# APM32F103x4 register map
File version: 1.0
CPU: CM3 r2p1, little endian, no MPU, no FPU, 4 interrupt priority bits
Registers are 32-bit, read-write, reset 0x0 unless marked. A register's access mark holds for its fields unless they carry their own. Offsets are from the block's base; [hi:lo] are bit positions; {n}, {i} and the like mark numbered series.

## PMU — Power control
Base 0x40007000
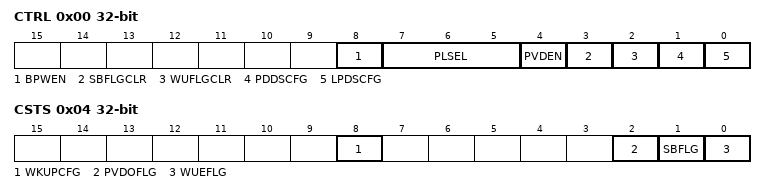
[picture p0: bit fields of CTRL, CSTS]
0x00 CTRL — Power control register (PMU_CTRL)
  [8] BPWEN — Disable Bakr Domain write protection
  [7:5] PLSEL — PVD Level Selection
  [4] PVDEN — Power Voltage Detector Enable
  [3] SBFLGCLR — Clear STANDBY Flag
  [2] WUFLGCLR — Clear Wake-up Flag
  [1] PDDSCFG — Power Down Deep Sleep
  [0] LPDSCFG — Low Power Deep Sleep
0x04 CSTS access per field — Power control/status register (PMU_CSTS)
  [8] WKUPCFG rw — Enable WKUP pin
  [2] PVDOFLG ro — PVD Output
  [1] SBFLG ro — STANDBY Flag
  [0] WUEFLG ro — Wake-Up Flag

## BAKPR — Bakr registers
Base 0x40006C00
{0x0+4i} DATA{i} (i=1..10) — Bakr data register (BAKPR_DATA)
  [15:0] DATA — Bakr data
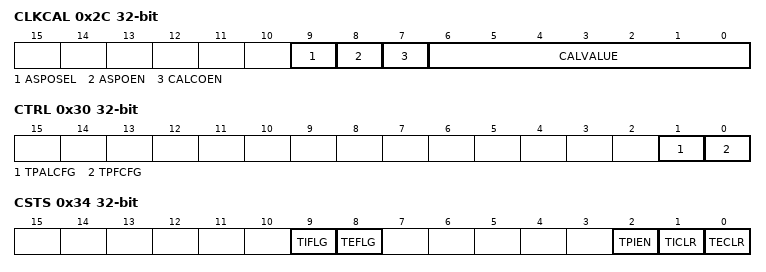
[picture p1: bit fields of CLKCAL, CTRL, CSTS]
0x2C CLKCAL — RTC clock calibration register (BAKPR_CLKCAL)
  [9] ASPOSEL — Alarm or second output selection
  [8] ASPOEN — Alarm or second output enable
  [7] CALCOEN — Calibration Clock Output
  [6:0] CALVALUE — Calibration value
0x30 CTRL — Bakr control register (BAKPR_CTRL)
  [1] TPALCFG — Tamper pin active level
  [0] TPFCFG — Tamper pin enable
0x34 CSTS access per field — Bakr control/status register (BAKPR_CSTS)
  [9] TIFLG ro — Tamper Interrupt Flag
  [8] TEFLG ro — Tamper Event Flag
  [2] TPIEN rw — Tamper Pin interrupt enable
  [1] TICLR wo — Clear Tamper Interrupt
  [0] TECLR wo — Clear Tamper event
{0x14+4i} DATA{i} (i=11..42) — Bakr data register (BAKPR_DATA)
  [15:0] DATA — Bakr data

## I2C1 — Inter integrated circuit 1
Base 0x40005400
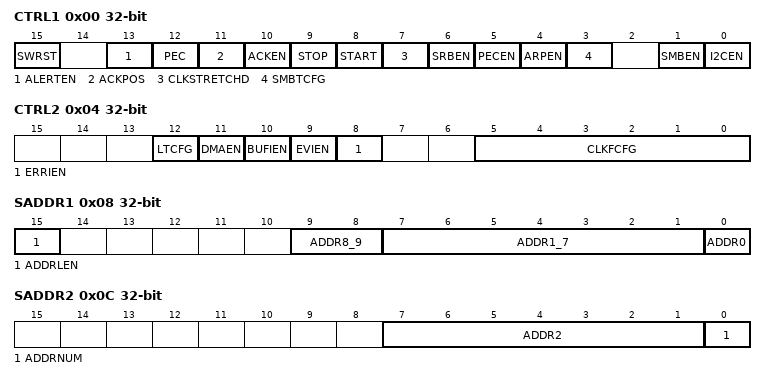
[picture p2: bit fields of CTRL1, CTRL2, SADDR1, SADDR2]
0x00 CTRL1 — Control register 1
  [15] SWRST — Software reset
  [13] ALERTEN — SMBus alert
  [12] PEC — Packet error checking
  [11] ACKPOS — Acknowledge/PEC Position (for data reception)
  [10] ACKEN — Acknowledge enable
  [9] STOP — Stop generation
  [8] START — Start generation
  [7] CLKSTRETCHD — Clock stretching disable (Slave mode)
  [6] SRBEN — General call enable
  [5] PECEN — PEC enable
  [4] ARPEN — ARP enable
  [3] SMBTCFG — SMBus type
  [1] SMBEN — SMBus mode
  [0] I2CEN — Peripheral enable
0x04 CTRL2 — Control register 2
  [12] LTCFG — DMA last transfer
  [11] DMAEN — DMA requests enable
  [10] BUFIEN — Buffer interrupt enable
  [9] EVIEN — Event interrupt enable
  [8] ERRIEN — Error interrupt enable
  [5:0] CLKFCFG — Peripheral clock frequency
0x08 SADDR1 — Own address register 1
  [15] ADDRLEN — Address Length Configure
  [9:8] ADDR8_9 — Interface address
  [7:1] ADDR1_7 — Interface address
  [0] ADDR0 — Interface address
0x0C SADDR2 — Own address register 2
  [7:1] ADDR2 — Interface address
  [0] ADDRNUM — Dual addressing mode enable
0x10 DATA
  [7:0] DATA — 8-bit data register
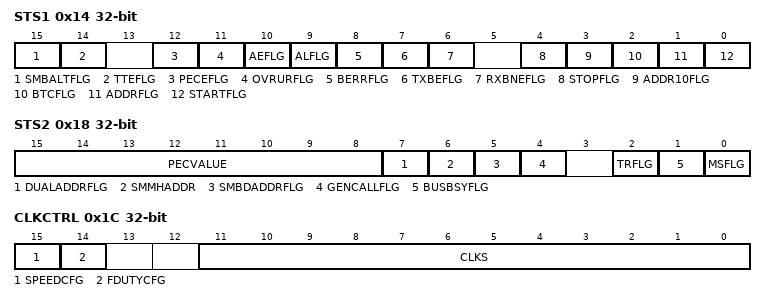
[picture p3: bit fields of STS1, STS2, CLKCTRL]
0x14 STS1 access per field — Status register 1
  [15] SMBALTFLG rw — SMBus alert
  [14] TTEFLG rw — Timeout or Tlow error
  [12] PECEFLG rw — PEC Error in reception
  [11] OVRURFLG rw — Overrun/Underrun
  [10] AEFLG rw — Acknowledge failure
  [9] ALFLG rw — Arbitration lost (master mode)
  [8] BERRFLG rw — Bus error
  [7] TXBEFLG ro — Data register empty (transmitters)
  [6] RXBNEFLG ro — Data register not empty (receivers)
  [4] STOPFLG ro — Stop detection (slave mode)
  [3] ADDR10FLG ro — 10-bit header sent (Master mode)
  [2] BTCFLG ro — Byte transfer finished
  [1] ADDRFLG ro — Address sent (master mode)/matched (slave mode)
  [0] STARTFLG ro — Start bit (Master mode)
0x18 STS2 ro — Status register 2
  [15:8] PECVALUE — acket error checking register
  [7] DUALADDRFLG — Dual flag (Slave mode)
  [6] SMMHADDR — SMBus host header (Slave mode)
  [5] SMBDADDRFLG — SMBus device default address (Slave mode)
  [4] GENCALLFLG — General call address (Slave mode)
  [2] TRFLG — Transmitter/receiver
  [1] BUSBSYFLG — Bus busy
  [0] MSFLG — Master/slave
0x1C CLKCTRL — Clock control register
  [15] SPEEDCFG — I2C master mode selection
  [14] FDUTYCFG — Fast mode duty cycle
  [11:0] CLKS — Clock control register in Fast/Standard mode (Master mode)
0x20 RISETMAX reset 0x2
  [5:0] RISETMAX — Maximum rise time in Fast/Standard mode (Master mode)
0x100 SWITCH reset 0x2 — I2C Switching register
  [0] SWITCH — I2C Switching
